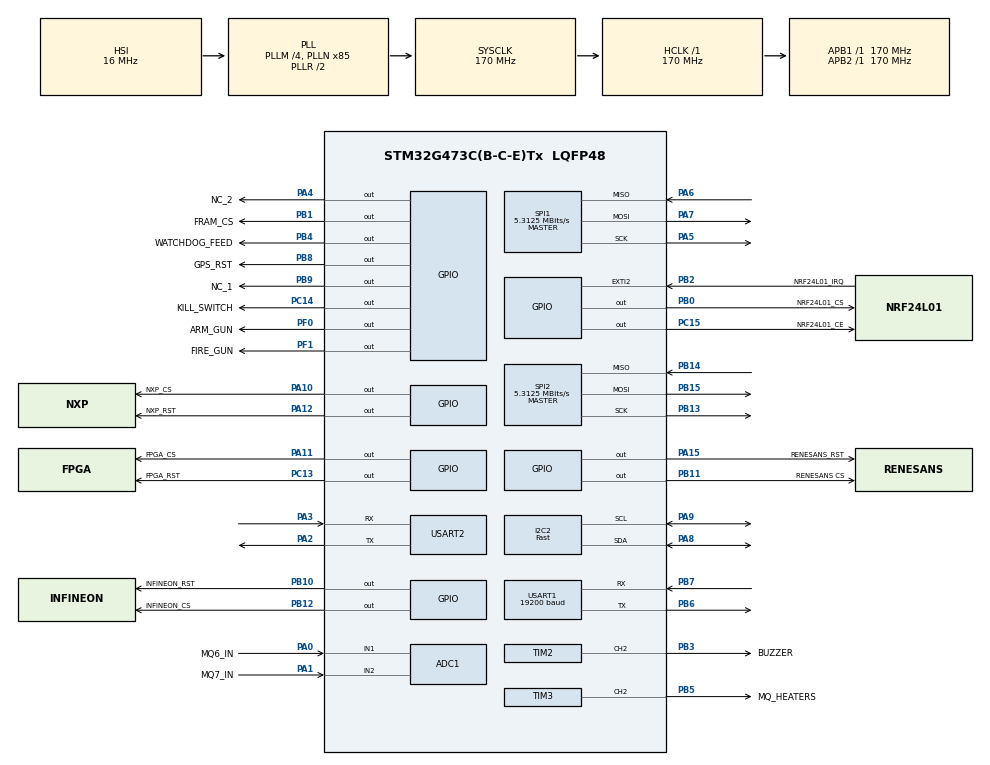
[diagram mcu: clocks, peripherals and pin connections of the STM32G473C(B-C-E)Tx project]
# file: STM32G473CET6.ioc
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ADC1.Channel-0\#ChannelRegularConversion=ADC_CHANNEL_1
ADC1.Channel-1\#ChannelRegularConversion=ADC_CHANNEL_2
ADC1.Channel-2\#ChannelRegularConversion=ADC_CHANNEL_VREFINT
ADC1.Channel-3\#ChannelRegularConversion=ADC_CHANNEL_TEMPSENSOR_ADC1
ADC1.ContinuousConvMode=DISABLE
ADC1.DMAContinuousRequests=DISABLE
ADC1.DataAlign=ADC_DATAALIGN_RIGHT
ADC1.EOCSelection=ADC_EOC_SEQ_CONV
ADC1.NbrOfConversion=4
ADC1.NbrOfConversionFlag=1
ADC1.OffsetNumber-1\#ChannelRegularConversion=ADC_OFFSET_NONE
ADC1.OffsetNumber-2\#ChannelRegularConversion=ADC_OFFSET_NONE
ADC1.OffsetNumber-3\#ChannelRegularConversion=ADC_OFFSET_NONE
ADC1.Overrun=ADC_OVR_DATA_PRESERVED
ADC1.Rank-1\#ChannelRegularConversion=2
ADC1.Rank-2\#ChannelRegularConversion=3
ADC1.Rank-3\#ChannelRegularConversion=4
ADC1.SamplingTime-0\#ChannelRegularConversion=ADC_SAMPLETIME_92CYCLES_5
ADC1.SamplingTime-1\#ChannelRegularConversion=ADC_SAMPLETIME_92CYCLES_5
ADC1.SamplingTime-2\#ChannelRegularConversion=ADC_SAMPLETIME_92CYCLES_5
ADC1.SamplingTime-3\#ChannelRegularConversion=ADC_SAMPLETIME_92CYCLES_5
ADC1.master=1
Dma.ADC1.10.Direction=DMA_PERIPH_TO_MEMORY
Dma.ADC1.10.EventEnable=DISABLE
Dma.ADC1.10.Instance=DMA2_Channel3
Dma.ADC1.10.MemDataAlignment=DMA_MDATAALIGN_WORD
Dma.ADC1.10.MemInc=DMA_MINC_ENABLE
Dma.ADC1.10.Mode=DMA_NORMAL
Dma.ADC1.10.PeriphDataAlignment=DMA_PDATAALIGN_WORD
Dma.ADC1.10.PeriphInc=DMA_PINC_DISABLE
Dma.ADC1.10.Polarity=HAL_DMAMUX_REQ_GEN_RISING
Dma.ADC1.10.Priority=DMA_PRIORITY_LOW
Dma.ADC1.10.RequestNumber=1
Dma.ADC1.10.SignalID=NONE
Dma.ADC1.10.SyncEnable=DISABLE
Dma.ADC1.10.SyncPolarity=HAL_DMAMUX_SYNC_NO_EVENT
Dma.ADC1.10.SyncRequestNumber=1
Dma.ADC1.10.SyncSignalID=NONE
Dma.I2C2_RX.1.Direction=DMA_PERIPH_TO_MEMORY
Dma.I2C2_RX.1.EventEnable=DISABLE
Dma.I2C2_RX.1.Instance=DMA1_Channel2
Dma.I2C2_RX.1.MemDataAlignment=DMA_MDATAALIGN_BYTE
Dma.I2C2_RX.1.MemInc=DMA_MINC_ENABLE
Dma.I2C2_RX.1.Mode=DMA_NORMAL
Dma.I2C2_RX.1.PeriphDataAlignment=DMA_PDATAALIGN_BYTE
Dma.I2C2_RX.1.PeriphInc=DMA_PINC_DISABLE
Dma.I2C2_RX.1.Polarity=HAL_DMAMUX_REQ_GEN_RISING
Dma.I2C2_RX.1.Priority=DMA_PRIORITY_MEDIUM
Dma.I2C2_RX.1.RequestNumber=1
Dma.I2C2_RX.1.SignalID=NONE
Dma.I2C2_RX.1.SyncEnable=DISABLE
Dma.I2C2_RX.1.SyncPolarity=HAL_DMAMUX_SYNC_NO_EVENT
Dma.I2C2_RX.1.SyncRequestNumber=1
Dma.I2C2_RX.1.SyncSignalID=NONE
Dma.I2C2_TX.0.Direction=DMA_MEMORY_TO_PERIPH
Dma.I2C2_TX.0.EventEnable=DISABLE
Dma.I2C2_TX.0.Instance=DMA1_Channel1
Dma.I2C2_TX.0.MemDataAlignment=DMA_MDATAALIGN_BYTE
Dma.I2C2_TX.0.MemInc=DMA_MINC_ENABLE
Dma.I2C2_TX.0.Mode=DMA_NORMAL
Dma.I2C2_TX.0.PeriphDataAlignment=DMA_PDATAALIGN_BYTE
Dma.I2C2_TX.0.PeriphInc=DMA_PINC_DISABLE
Dma.I2C2_TX.0.Polarity=HAL_DMAMUX_REQ_GEN_RISING
Dma.I2C2_TX.0.Priority=DMA_PRIORITY_MEDIUM
Dma.I2C2_TX.0.RequestNumber=1
Dma.I2C2_TX.0.SignalID=NONE
Dma.I2C2_TX.0.SyncEnable=DISABLE
Dma.I2C2_TX.0.SyncPolarity=HAL_DMAMUX_SYNC_NO_EVENT
Dma.I2C2_TX.0.SyncRequestNumber=1
Dma.I2C2_TX.0.SyncSignalID=NONE
Dma.Request0=I2C2_TX
Dma.Request1=I2C2_RX
Dma.Request10=ADC1
Dma.Request2=SPI1_RX
Dma.Request3=SPI1_TX
Dma.Request4=SPI2_RX
Dma.Request5=SPI2_TX
Dma.Request6=USART1_RX
Dma.Request7=USART1_TX
Dma.Request8=USART2_RX
Dma.Request9=USART2_TX
Dma.SPI1_RX.2.Direction=DMA_PERIPH_TO_MEMORY
Dma.SPI1_RX.2.EventEnable=DISABLE
Dma.SPI1_RX.2.Instance=DMA1_Channel3
Dma.SPI1_RX.2.MemDataAlignment=DMA_MDATAALIGN_BYTE
Dma.SPI1_RX.2.MemInc=DMA_MINC_ENABLE
Dma.SPI1_RX.2.Mode=DMA_NORMAL
Dma.SPI1_RX.2.PeriphDataAlignment=DMA_PDATAALIGN_BYTE
Dma.SPI1_RX.2.PeriphInc=DMA_PINC_DISABLE
Dma.SPI1_RX.2.Polarity=HAL_DMAMUX_REQ_GEN_RISING
Dma.SPI1_RX.2.Priority=DMA_PRIORITY_HIGH
Dma.SPI1_RX.2.RequestNumber=1
Dma.SPI1_RX.2.SignalID=NONE
Dma.SPI1_RX.2.SyncEnable=DISABLE
Dma.SPI1_RX.2.SyncPolarity=HAL_DMAMUX_SYNC_NO_EVENT
Dma.SPI1_RX.2.SyncRequestNumber=1
Dma.SPI1_RX.2.SyncSignalID=NONE
Dma.SPI1_TX.3.Direction=DMA_MEMORY_TO_PERIPH
Dma.SPI1_TX.3.EventEnable=DISABLE
Dma.SPI1_TX.3.Instance=DMA1_Channel4
Dma.SPI1_TX.3.MemDataAlignment=DMA_MDATAALIGN_BYTE
Dma.SPI1_TX.3.MemInc=DMA_MINC_ENABLE
Dma.SPI1_TX.3.Mode=DMA_NORMAL
Dma.SPI1_TX.3.PeriphDataAlignment=DMA_PDATAALIGN_BYTE
Dma.SPI1_TX.3.PeriphInc=DMA_PINC_DISABLE
Dma.SPI1_TX.3.Polarity=HAL_DMAMUX_REQ_GEN_RISING
Dma.SPI1_TX.3.Priority=DMA_PRIORITY_HIGH
Dma.SPI1_TX.3.RequestNumber=1
Dma.SPI1_TX.3.SignalID=NONE
Dma.SPI1_TX.3.SyncEnable=DISABLE
Dma.SPI1_TX.3.SyncPolarity=HAL_DMAMUX_SYNC_NO_EVENT
Dma.SPI1_TX.3.SyncRequestNumber=1
Dma.SPI1_TX.3.SyncSignalID=NONE
Dma.SPI2_RX.4.Direction=DMA_PERIPH_TO_MEMORY
Dma.SPI2_RX.4.EventEnable=DISABLE
Dma.SPI2_RX.4.Instance=DMA1_Channel5
Dma.SPI2_RX.4.MemDataAlignment=DMA_MDATAALIGN_BYTE
Dma.SPI2_RX.4.MemInc=DMA_MINC_ENABLE
Dma.SPI2_RX.4.Mode=DMA_NORMAL
Dma.SPI2_RX.4.PeriphDataAlignment=DMA_PDATAALIGN_BYTE
Dma.SPI2_RX.4.PeriphInc=DMA_PINC_DISABLE
Dma.SPI2_RX.4.Polarity=HAL_DMAMUX_REQ_GEN_RISING
Dma.SPI2_RX.4.Priority=DMA_PRIORITY_VERY_HIGH
Dma.SPI2_RX.4.RequestNumber=1
Dma.SPI2_RX.4.SignalID=NONE
Dma.SPI2_RX.4.SyncEnable=DISABLE
Dma.SPI2_RX.4.SyncPolarity=HAL_DMAMUX_SYNC_NO_EVENT
Dma.SPI2_RX.4.SyncRequestNumber=1
Dma.SPI2_RX.4.SyncSignalID=NONE
Dma.SPI2_TX.5.Direction=DMA_MEMORY_TO_PERIPH
Dma.SPI2_TX.5.EventEnable=DISABLE
Dma.SPI2_TX.5.Instance=DMA1_Channel6
Dma.SPI2_TX.5.MemDataAlignment=DMA_MDATAALIGN_BYTE
Dma.SPI2_TX.5.MemInc=DMA_MINC_ENABLE
Dma.SPI2_TX.5.Mode=DMA_NORMAL
Dma.SPI2_TX.5.PeriphDataAlignment=DMA_PDATAALIGN_BYTE
Dma.SPI2_TX.5.PeriphInc=DMA_PINC_DISABLE
Dma.SPI2_TX.5.Polarity=HAL_DMAMUX_REQ_GEN_RISING
Dma.SPI2_TX.5.Priority=DMA_PRIORITY_VERY_HIGH
Dma.SPI2_TX.5.RequestNumber=1
Dma.SPI2_TX.5.SignalID=NONE
Dma.SPI2_TX.5.SyncEnable=DISABLE
Dma.SPI2_TX.5.SyncPolarity=HAL_DMAMUX_SYNC_NO_EVENT
Dma.SPI2_TX.5.SyncRequestNumber=1
Dma.SPI2_TX.5.SyncSignalID=NONE
Dma.USART1_RX.6.Direction=DMA_PERIPH_TO_MEMORY
Dma.USART1_RX.6.EventEnable=DISABLE
Dma.USART1_RX.6.Instance=DMA1_Channel7
Dma.USART1_RX.6.MemDataAlignment=DMA_MDATAALIGN_BYTE
Dma.USART1_RX.6.MemInc=DMA_MINC_ENABLE
Dma.USART1_RX.6.Mode=DMA_CIRCULAR
Dma.USART1_RX.6.PeriphDataAlignment=DMA_PDATAALIGN_BYTE
Dma.USART1_RX.6.PeriphInc=DMA_PINC_DISABLE
Dma.USART1_RX.6.Polarity=HAL_DMAMUX_REQ_GEN_RISING
Dma.USART1_RX.6.Priority=DMA_PRIORITY_LOW
Dma.USART1_RX.6.RequestNumber=1
Dma.USART1_RX.6.SignalID=NONE
Dma.USART1_RX.6.SyncEnable=DISABLE
Dma.USART1_RX.6.SyncPolarity=HAL_DMAMUX_SYNC_NO_EVENT
Dma.USART1_RX.6.SyncRequestNumber=1
Dma.USART1_RX.6.SyncSignalID=NONE
Dma.USART1_TX.7.Direction=DMA_MEMORY_TO_PERIPH
Dma.USART1_TX.7.EventEnable=DISABLE
Dma.USART1_TX.7.Instance=DMA1_Channel8
Dma.USART1_TX.7.MemDataAlignment=DMA_MDATAALIGN_BYTE
Dma.USART1_TX.7.MemInc=DMA_MINC_ENABLE
Dma.USART1_TX.7.Mode=DMA_NORMAL
Dma.USART1_TX.7.PeriphDataAlignment=DMA_PDATAALIGN_BYTE
Dma.USART1_TX.7.PeriphInc=DMA_PINC_DISABLE
Dma.USART1_TX.7.Polarity=HAL_DMAMUX_REQ_GEN_RISING
Dma.USART1_TX.7.Priority=DMA_PRIORITY_LOW
Dma.USART1_TX.7.RequestNumber=1
Dma.USART1_TX.7.SignalID=NONE
Dma.USART1_TX.7.SyncEnable=DISABLE
Dma.USART1_TX.7.SyncPolarity=HAL_DMAMUX_SYNC_NO_EVENT
Dma.USART1_TX.7.SyncRequestNumber=1
Dma.USART1_TX.7.SyncSignalID=NONE
Dma.USART2_RX.8.Direction=DMA_PERIPH_TO_MEMORY
Dma.USART2_RX.8.EventEnable=DISABLE
Dma.USART2_RX.8.Instance=DMA2_Channel1
Dma.USART2_RX.8.MemDataAlignment=DMA_MDATAALIGN_BYTE
Dma.USART2_RX.8.MemInc=DMA_MINC_ENABLE
Dma.USART2_RX.8.Mode=DMA_NORMAL
Dma.USART2_RX.8.PeriphDataAlignment=DMA_PDATAALIGN_BYTE
Dma.USART2_RX.8.PeriphInc=DMA_PINC_DISABLE
Dma.USART2_RX.8.Polarity=HAL_DMAMUX_REQ_GEN_RISING
Dma.USART2_RX.8.Priority=DMA_PRIORITY_LOW
Dma.USART2_RX.8.RequestNumber=1
Dma.USART2_RX.8.SignalID=NONE
Dma.USART2_RX.8.SyncEnable=DISABLE
Dma.USART2_RX.8.SyncPolarity=HAL_DMAMUX_SYNC_NO_EVENT
Dma.USART2_RX.8.SyncRequestNumber=1
Dma.USART2_RX.8.SyncSignalID=NONE
Dma.USART2_TX.9.Direction=DMA_MEMORY_TO_PERIPH
Dma.USART2_TX.9.EventEnable=DISABLE
Dma.USART2_TX.9.Instance=DMA2_Channel2
Dma.USART2_TX.9.MemDataAlignment=DMA_MDATAALIGN_BYTE
Dma.USART2_TX.9.MemInc=DMA_MINC_ENABLE
Dma.USART2_TX.9.Mode=DMA_NORMAL
Dma.USART2_TX.9.PeriphDataAlignment=DMA_PDATAALIGN_BYTE
Dma.USART2_TX.9.PeriphInc=DMA_PINC_DISABLE
Dma.USART2_TX.9.Polarity=HAL_DMAMUX_REQ_GEN_RISING
Dma.USART2_TX.9.Priority=DMA_PRIORITY_LOW
Dma.USART2_TX.9.RequestNumber=1
Dma.USART2_TX.9.SignalID=NONE
Dma.USART2_TX.9.SyncEnable=DISABLE
Dma.USART2_TX.9.SyncPolarity=HAL_DMAMUX_SYNC_NO_EVENT
Dma.USART2_TX.9.SyncRequestNumber=1
Dma.USART2_TX.9.SyncSignalID=NONE
I2C2.I2C_Speed_Mode=I2C_Fast
I2C2.Timing=0x40621236
Mcu.Family=STM32G4
Mcu.Name=STM32G473C(B-C-E)Tx
Mcu.Package=LQFP48
NVIC.DMA1_Channel1_IRQn=true\:8\:0\:true\:false\:true\:false\:false\:true\:true
NVIC.DMA1_Channel2_IRQn=true\:8\:0\:true\:false\:true\:false\:false\:true\:true
NVIC.DMA1_Channel3_IRQn=true\:2\:0\:true\:false\:true\:false\:false\:true\:true
NVIC.DMA1_Channel4_IRQn=true\:2\:0\:true\:false\:true\:false\:false\:true\:true
NVIC.DMA1_Channel5_IRQn=true\:5\:0\:true\:false\:true\:false\:false\:true\:true
NVIC.DMA1_Channel6_IRQn=true\:5\:0\:true\:false\:true\:false\:false\:true\:true
NVIC.DMA1_Channel7_IRQn=true\:9\:0\:true\:false\:true\:false\:false\:true\:true
NVIC.DMA1_Channel8_IRQn=true\:9\:0\:true\:false\:true\:false\:false\:true\:true
NVIC.DMA2_Channel1_IRQn=true\:0\:0\:false\:false\:true\:false\:false\:true\:true
NVIC.DMA2_Channel2_IRQn=true\:0\:0\:false\:false\:true\:false\:false\:true\:true
NVIC.DMA2_Channel3_IRQn=true\:3\:0\:true\:false\:true\:true\:false\:true\:true
NVIC.EXTI2_IRQn=true\:5\:0\:true\:false\:true\:false\:true\:true\:true
NVIC.PriorityGroup=NVIC_PRIORITYGROUP_4
NVIC.TIM6_DAC_IRQn=true\:15\:0\:true\:false\:true\:false\:false\:true\:true
NVIC.TimeBase=TIM6_DAC_IRQn
NVIC.TimeBaseIP=TIM6
NVIC.USART1_IRQn=true\:0\:0\:false\:false\:true\:false\:true\:true\:true
NVIC.USART2_IRQn=true\:0\:0\:false\:false\:true\:false\:true\:true\:true
PA0.GPIO_Label=MQ6_IN
PA0.Mode=IN1-Single-Ended
PA0.Signal=ADC1_IN1
PA1.GPIO_Label=MQ7_IN
PA1.Mode=IN2-Single-Ended
PA1.Signal=ADC1_IN2
PA10.GPIO_Label=NXP_CS
PA10.Signal=GPIO_Output
PA11.GPIO_Label=FPGA_CS
PA11.Signal=GPIO_Output
PA12.GPIO_Label=NXP_RST
PA12.Signal=GPIO_Output
PA13.Mode=Serial_Wire
PA13.Signal=SYS_JTMS-SWDIO
PA14.Mode=Serial_Wire
PA14.Signal=SYS_JTCK-SWCLK
PA15.GPIO_Label=RENESANS_RST
PA15.Signal=GPIO_Output
PA2.Mode=Asynchronous
PA2.Signal=USART2_TX
PA3.GPIO_PuPd=GPIO_PULLUP
PA3.Mode=Asynchronous
PA3.Signal=USART2_RX
PA4.GPIO_Label=NC_2
PA4.Signal=GPIO_Output
PA5.GPIO_Speed=GPIO_SPEED_FREQ_HIGH
PA5.Mode=Full_Duplex_Master
PA5.Signal=SPI1_SCK
PA6.GPIO_Speed=GPIO_SPEED_FREQ_HIGH
PA6.Mode=Full_Duplex_Master
PA6.Signal=SPI1_MISO
PA7.GPIO_Speed=GPIO_SPEED_FREQ_HIGH
PA7.Mode=Full_Duplex_Master
PA7.Signal=SPI1_MOSI
PA8.Mode=I2C
PA8.Signal=I2C2_SDA
PA9.Mode=I2C
PA9.Signal=I2C2_SCL
PB0.GPIO_Label=NRF24L01_CS
PB0.Signal=GPIO_Output
PB1.GPIO_Label=FRAM_CS
PB1.Signal=GPIO_Output
PB10.GPIO_Label=INFINEON_RST
PB10.Signal=GPIO_Output
PB11.GPIO_Label=RENESANS CS
PB11.Signal=GPIO_Output
PB12.GPIO_Label=INFINEON_CS
PB12.Signal=GPIO_Output
PB13.GPIO_Speed=GPIO_SPEED_FREQ_VERY_HIGH
PB13.Mode=Full_Duplex_Master
PB13.Signal=SPI2_SCK
PB14.GPIO_Speed=GPIO_SPEED_FREQ_VERY_HIGH
PB14.Mode=Full_Duplex_Master
PB14.Signal=SPI2_MISO
PB15.GPIO_PuPd=GPIO_NOPULL
PB15.GPIO_Speed=GPIO_SPEED_FREQ_VERY_HIGH
PB15.Mode=Full_Duplex_Master
PB15.Signal=SPI2_MOSI
PB2.GPIO_Label=NRF24L01_IRQ
PB2.GPIO_ModeDefaultEXTI=GPIO_MODE_IT_FALLING
PB2.GPIO_PuPd=GPIO_NOPULL
PB2.Signal=GPXTI2
PB3.GPIO_Label=BUZZER
PB3.GPIO_Speed=GPIO_SPEED_FREQ_LOW
PB3.Signal=S_TIM2_CH2
PB4.GPIO_Label=WATCHDOG_FEED
PB4.Signal=GPIO_Output
PB5.GPIO_Label=MQ_HEATERS
PB5.GPIO_Speed=GPIO_SPEED_FREQ_VERY_HIGH
PB5.Signal=S_TIM3_CH2
PB6.Mode=Asynchronous
PB6.Signal=USART1_TX
PB7.GPIO_ModeDefaultPP=GPIO_MODE_AF_PP
PB7.GPIO_PuPd=GPIO_PULLUP
PB7.Mode=Asynchronous
PB7.Signal=USART1_RX
PB8-BOOT0.GPIO_Label=GPS_RST
PB8-BOOT0.Signal=GPIO_Output
PB9.GPIO_Label=NC_1
PB9.Signal=GPIO_Output
PC13.GPIO_Label=FPGA_RST
PC13.Signal=GPIO_Output
PC14-OSC32_IN.GPIO_Label=KILL_SWITCH
PC14-OSC32_IN.Signal=GPIO_Output
PC15-OSC32_OUT.GPIO_Label=NRF24L01_CE
PC15-OSC32_OUT.Signal=GPIO_Output
PF0-OSC_IN.GPIO_Label=ARM_GUN
PF0-OSC_IN.Signal=GPIO_Output
PF1-OSC_OUT.GPIO_Label=FIRE_GUN
PF1-OSC_OUT.Signal=GPIO_Output
ProjectManager.HeapSize=0x200
ProjectManager.StackSize=0x400
ProjectManager.TargetToolchain=STM32CubeIDE
RCC.ADC12Freq_Value=170000000
RCC.ADC345Freq_Value=170000000
RCC.AHBFreq_Value=170000000
RCC.APB1Freq_Value=170000000
RCC.APB1TimFreq_Value=170000000
RCC.APB2Freq_Value=170000000
RCC.APB2TimFreq_Value=170000000
RCC.CortexFreq_Value=170000000
RCC.EXTERNAL_CLOCK_VALUE=12288000
RCC.HCLKFreq_Value=170000000
RCC.HSE_VALUE=8000000
RCC.HSI48_VALUE=48000000
RCC.HSI_VALUE=16000000
RCC.LSE_VALUE=32768
RCC.PLLM=RCC_PLLM_DIV4
RCC.PLLN=85
RCC.SYSCLKFreq_VALUE=170000000
RCC.SYSCLKSource=RCC_SYSCLKSOURCE_PLLCLK
RCC.USBFreq_Value=170000000
RCC.VCOOutputFreq_Value=340000000
SH.S_TIM2_CH2.0=TIM2_CH2,PWM Generation2 CH2
SH.S_TIM3_CH2.0=TIM3_CH2,PWM Generation2 CH2
SPI1.BaudRatePrescaler=SPI_BAUDRATEPRESCALER_32
SPI1.CalculateBaudRate=5.3125 MBits/s
SPI1.DataSize=SPI_DATASIZE_8BIT
SPI1.Direction=SPI_DIRECTION_2LINES
SPI1.FirstBit=SPI_FIRSTBIT_MSB
SPI1.Mode=SPI_MODE_MASTER
SPI1.VirtualType=VM_MASTER
SPI2.BaudRatePrescaler=SPI_BAUDRATEPRESCALER_32
SPI2.CalculateBaudRate=5.3125 MBits/s
SPI2.DataSize=SPI_DATASIZE_8BIT
SPI2.Direction=SPI_DIRECTION_2LINES
SPI2.Mode=SPI_MODE_MASTER
SPI2.VirtualType=VM_MASTER
STMicroelectronics.X-CUBE-AZRTOS-G4.2.0.0.AZRTOS_APP_MEM_ALLOCATION_METHOD=1
STMicroelectronics.X-CUBE-AZRTOS-G4.2.0.0.TX_APP_GENERATE_INIT_CODE=true
STMicroelectronics.X-CUBE-AZRTOS-G4.2.0.0.TX_TIMER_TICKS_PER_SECOND=2000
STMicroelectronics.X-CUBE-AZRTOS-G4.2.0.0.ThreadXCcRTOSJjThreadXJjCore=true
STMicroelectronics.X-CUBE-AZRTOS-G4.2.0.0_IsAnAzureRtosMw=true
TIM2.AutoReloadPreload=TIM_AUTORELOAD_PRELOAD_ENABLE
TIM2.Channel-PWM\ Generation2\ CH2=TIM_CHANNEL_2
TIM2.PeriodNoDither=999
TIM2.Prescaler=169
TIM3.AutoReloadPreload=TIM_AUTORELOAD_PRELOAD_ENABLE
TIM3.Channel-PWM\ Generation2\ CH2=TIM_CHANNEL_2
TIM3.PeriodNoDither=999
TIM3.Prescaler=169
USART1.BaudRate=19200
USART1.VirtualMode-Asynchronous=VM_ASYNC
USART2.VirtualMode-Asynchronous=VM_ASYNC
VP_ADC1_TempSens_Input.Mode=IN-TempSens
VP_ADC1_Vref_Input.Mode=IN-Vrefint
VP_CORDIC_VS_CORDIC.Mode=CORDIC_Activate
VP_STMicroelectronics.X-CUBE-AZRTOS-G4_VS_RTOSJjThreadX_6.2.0_2.0.0.Mode=RTOSJjThreadX
VP_SYS_VS_DBSignals.Mode=DisableDeadBatterySignals
VP_SYS_VS_tim6.Mode=TIM6
VP_TIM2_VS_ClockSourceINT.Mode=Internal
VP_TIM3_VS_ClockSourceINT.Mode=Internal
board=custom

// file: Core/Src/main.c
/* USER CODE BEGIN Header */
/**
  ******************************************************************************
  * @file           : main.c
  * @brief          : Main program body
  ******************************************************************************
  * @attention
  *
  * Copyright (c) 2025 STMicroelectronics.
  * All rights reserved.
  *
  * This software is licensed under terms that can be found in the LICENSE file
  * in the root directory of this software component.
  * If no LICENSE file comes with this software, it is provided AS-IS.
  *
  ******************************************************************************
  */
/* USER CODE END Header */
#include "app_threadx.h"
#include "main.h"

ADC_HandleTypeDef hadc1;
DMA_HandleTypeDef hdma_adc1;

CORDIC_HandleTypeDef hcordic;

I2C_HandleTypeDef hi2c2;
DMA_HandleTypeDef hdma_i2c2_tx;
DMA_HandleTypeDef hdma_i2c2_rx;

SPI_HandleTypeDef hspi1;
SPI_HandleTypeDef hspi2;
DMA_HandleTypeDef hdma_spi1_rx;
DMA_HandleTypeDef hdma_spi1_tx;
DMA_HandleTypeDef hdma_spi2_rx;
DMA_HandleTypeDef hdma_spi2_tx;

TIM_HandleTypeDef htim2;
TIM_HandleTypeDef htim3;

UART_HandleTypeDef huart1;
UART_HandleTypeDef huart2;
DMA_HandleTypeDef hdma_usart1_rx;
DMA_HandleTypeDef hdma_usart1_tx;
DMA_HandleTypeDef hdma_usart2_rx;
DMA_HandleTypeDef hdma_usart2_tx;

void SystemClock_Config(void);
static void MX_GPIO_Init(void);
static void MX_DMA_Init(void);
static void MX_ADC1_Init(void);
static void MX_I2C2_Init(void);
static void MX_SPI1_Init(void);
static void MX_SPI2_Init(void);
static void MX_USART1_UART_Init(void);
static void MX_USART2_UART_Init(void);
static void MX_CORDIC_Init(void);
static void MX_TIM3_Init(void);
static void MX_TIM2_Init(void);

int main(void)
{

  /* MCU Configuration--------------------------------------------------------*/

  /* Reset of all peripherals, Initializes the Flash interface and the Systick. */
  HAL_Init();

  /* Configure the system clock */
  SystemClock_Config();

  /* Initialize all configured peripherals */
  MX_GPIO_Init();
  MX_DMA_Init();
  MX_ADC1_Init();
  MX_I2C2_Init();
  MX_SPI1_Init();
  MX_SPI2_Init();
  MX_USART1_UART_Init();
  MX_USART2_UART_Init();
  MX_CORDIC_Init();
  MX_TIM3_Init();
  MX_TIM2_Init();

  MX_ThreadX_Init();

  /* We should never get here as control is now taken by the scheduler */

  /* Infinite loop */
  while (1)
  {

  }
}

void SystemClock_Config(void)
{
  RCC_OscInitTypeDef RCC_OscInitStruct = {0};
  RCC_ClkInitTypeDef RCC_ClkInitStruct = {0};

  /** Configure the main internal regulator output voltage
  */
  HAL_PWREx_ControlVoltageScaling(PWR_REGULATOR_VOLTAGE_SCALE1_BOOST);

  /** Initializes the RCC Oscillators according to the specified parameters
  * in the RCC_OscInitTypeDef structure.
  */
  RCC_OscInitStruct.OscillatorType = RCC_OSCILLATORTYPE_HSI;
  RCC_OscInitStruct.HSIState = RCC_HSI_ON;
  RCC_OscInitStruct.HSICalibrationValue = RCC_HSICALIBRATION_DEFAULT;
  RCC_OscInitStruct.PLL.PLLState = RCC_PLL_ON;
  RCC_OscInitStruct.PLL.PLLSource = RCC_PLLSOURCE_HSI;
  RCC_OscInitStruct.PLL.PLLM = RCC_PLLM_DIV4;
  RCC_OscInitStruct.PLL.PLLN = 85;
  RCC_OscInitStruct.PLL.PLLP = RCC_PLLP_DIV2;
  RCC_OscInitStruct.PLL.PLLQ = RCC_PLLQ_DIV2;
  RCC_OscInitStruct.PLL.PLLR = RCC_PLLR_DIV2;
  if (HAL_RCC_OscConfig(&RCC_OscInitStruct) != HAL_OK)
  {
    Error_Handler();
  }

  /** Initializes the CPU, AHB and APB buses clocks
  */
  RCC_ClkInitStruct.ClockType = RCC_CLOCKTYPE_HCLK|RCC_CLOCKTYPE_SYSCLK
                              |RCC_CLOCKTYPE_PCLK1|RCC_CLOCKTYPE_PCLK2;
  RCC_ClkInitStruct.SYSCLKSource = RCC_SYSCLKSOURCE_PLLCLK;
  RCC_ClkInitStruct.AHBCLKDivider = RCC_SYSCLK_DIV1;
  RCC_ClkInitStruct.APB1CLKDivider = RCC_HCLK_DIV1;
  RCC_ClkInitStruct.APB2CLKDivider = RCC_HCLK_DIV1;

  if (HAL_RCC_ClockConfig(&RCC_ClkInitStruct, FLASH_LATENCY_4) != HAL_OK)
  {
    Error_Handler();
  }
}

static void MX_ADC1_Init(void)
{

  ADC_MultiModeTypeDef multimode = {0};
  ADC_ChannelConfTypeDef sConfig = {0};

  /** Common config
  */
  hadc1.Instance = ADC1;
  hadc1.Init.ClockPrescaler = ADC_CLOCK_SYNC_PCLK_DIV4;
  hadc1.Init.Resolution = ADC_RESOLUTION_12B;
  hadc1.Init.DataAlign = ADC_DATAALIGN_RIGHT;
  hadc1.Init.GainCompensation = 0;
  hadc1.Init.ScanConvMode = ADC_SCAN_ENABLE;
  hadc1.Init.EOCSelection = ADC_EOC_SEQ_CONV;
  hadc1.Init.LowPowerAutoWait = DISABLE;
  hadc1.Init.ContinuousConvMode = DISABLE;
  hadc1.Init.NbrOfConversion = 4;
  hadc1.Init.DiscontinuousConvMode = DISABLE;
  hadc1.Init.ExternalTrigConv = ADC_SOFTWARE_START;
  hadc1.Init.ExternalTrigConvEdge = ADC_EXTERNALTRIGCONVEDGE_NONE;
  hadc1.Init.DMAContinuousRequests = DISABLE;
  hadc1.Init.Overrun = ADC_OVR_DATA_PRESERVED;
  hadc1.Init.OversamplingMode = DISABLE;
  if (HAL_ADC_Init(&hadc1) != HAL_OK)
  {
    Error_Handler();
  }

  /** Configure the ADC multi-mode
  */
  multimode.Mode = ADC_MODE_INDEPENDENT;
  if (HAL_ADCEx_MultiModeConfigChannel(&hadc1, &multimode) != HAL_OK)
  {
    Error_Handler();
  }

  /** Configure Regular Channel
  */
  sConfig.Channel = ADC_CHANNEL_1;
  sConfig.Rank = ADC_REGULAR_RANK_1;
  sConfig.SamplingTime = ADC_SAMPLETIME_92CYCLES_5;
  sConfig.SingleDiff = ADC_SINGLE_ENDED;
  sConfig.OffsetNumber = ADC_OFFSET_NONE;
  sConfig.Offset = 0;
  if (HAL_ADC_ConfigChannel(&hadc1, &sConfig) != HAL_OK)
  {
    Error_Handler();
  }

  /** Configure Regular Channel
  */
  sConfig.Channel = ADC_CHANNEL_2;
  sConfig.Rank = ADC_REGULAR_RANK_2;
  if (HAL_ADC_ConfigChannel(&hadc1, &sConfig) != HAL_OK)
  {
    Error_Handler();
  }

  /** Configure Regular Channel
  */
  sConfig.Channel = ADC_CHANNEL_VREFINT;
  sConfig.Rank = ADC_REGULAR_RANK_3;
  if (HAL_ADC_ConfigChannel(&hadc1, &sConfig) != HAL_OK)
  {
    Error_Handler();
  }

  /** Configure Regular Channel
  */
  sConfig.Channel = ADC_CHANNEL_TEMPSENSOR_ADC1;
  sConfig.Rank = ADC_REGULAR_RANK_4;
  if (HAL_ADC_ConfigChannel(&hadc1, &sConfig) != HAL_OK)
  {
    Error_Handler();
  }

}

static void MX_CORDIC_Init(void)
{

  hcordic.Instance = CORDIC;
  if (HAL_CORDIC_Init(&hcordic) != HAL_OK)
  {
    Error_Handler();
  }

}

static void MX_I2C2_Init(void)
{

  hi2c2.Instance = I2C2;
  hi2c2.Init.Timing = 0x40621236;
  hi2c2.Init.OwnAddress1 = 0;
  hi2c2.Init.AddressingMode = I2C_ADDRESSINGMODE_7BIT;
  hi2c2.Init.DualAddressMode = I2C_DUALADDRESS_DISABLE;
  hi2c2.Init.OwnAddress2 = 0;
  hi2c2.Init.OwnAddress2Masks = I2C_OA2_NOMASK;
  hi2c2.Init.GeneralCallMode = I2C_GENERALCALL_DISABLE;
  hi2c2.Init.NoStretchMode = I2C_NOSTRETCH_DISABLE;
  if (HAL_I2C_Init(&hi2c2) != HAL_OK)
  {
    Error_Handler();
  }

  /** Configure Analogue filter
  */
  if (HAL_I2CEx_ConfigAnalogFilter(&hi2c2, I2C_ANALOGFILTER_ENABLE) != HAL_OK)
  {
    Error_Handler();
  }

  /** Configure Digital filter
  */
  if (HAL_I2CEx_ConfigDigitalFilter(&hi2c2, 0) != HAL_OK)
  {
    Error_Handler();
  }

}

static void MX_SPI1_Init(void)
{

  /* SPI1 parameter configuration*/
  hspi1.Instance = SPI1;
  hspi1.Init.Mode = SPI_MODE_MASTER;
  hspi1.Init.Direction = SPI_DIRECTION_2LINES;
  hspi1.Init.DataSize = SPI_DATASIZE_8BIT;
  hspi1.Init.CLKPolarity = SPI_POLARITY_LOW;
  hspi1.Init.CLKPhase = SPI_PHASE_1EDGE;
  hspi1.Init.NSS = SPI_NSS_SOFT;
  hspi1.Init.BaudRatePrescaler = SPI_BAUDRATEPRESCALER_32;
  hspi1.Init.FirstBit = SPI_FIRSTBIT_MSB;
  hspi1.Init.TIMode = SPI_TIMODE_DISABLE;
  hspi1.Init.CRCCalculation = SPI_CRCCALCULATION_DISABLE;
  hspi1.Init.CRCPolynomial = 7;
  hspi1.Init.CRCLength = SPI_CRC_LENGTH_DATASIZE;
  hspi1.Init.NSSPMode = SPI_NSS_PULSE_ENABLE;
  if (HAL_SPI_Init(&hspi1) != HAL_OK)
  {
    Error_Handler();
  }

}

static void MX_SPI2_Init(void)
{

  /* SPI2 parameter configuration*/
  hspi2.Instance = SPI2;
  hspi2.Init.Mode = SPI_MODE_MASTER;
  hspi2.Init.Direction = SPI_DIRECTION_2LINES;
  hspi2.Init.DataSize = SPI_DATASIZE_8BIT;
  hspi2.Init.CLKPolarity = SPI_POLARITY_LOW;
  hspi2.Init.CLKPhase = SPI_PHASE_1EDGE;
  hspi2.Init.NSS = SPI_NSS_SOFT;
  hspi2.Init.BaudRatePrescaler = SPI_BAUDRATEPRESCALER_32;
  hspi2.Init.FirstBit = SPI_FIRSTBIT_MSB;
  hspi2.Init.TIMode = SPI_TIMODE_DISABLE;
  hspi2.Init.CRCCalculation = SPI_CRCCALCULATION_DISABLE;
  hspi2.Init.CRCPolynomial = 7;
  hspi2.Init.CRCLength = SPI_CRC_LENGTH_DATASIZE;
  hspi2.Init.NSSPMode = SPI_NSS_PULSE_ENABLE;
  if (HAL_SPI_Init(&hspi2) != HAL_OK)
  {
    Error_Handler();
  }

}

static void MX_TIM2_Init(void)
{

  TIM_ClockConfigTypeDef sClockSourceConfig = {0};
  TIM_MasterConfigTypeDef sMasterConfig = {0};
  TIM_OC_InitTypeDef sConfigOC = {0};

  htim2.Instance = TIM2;
  htim2.Init.Prescaler = 169;
  htim2.Init.CounterMode = TIM_COUNTERMODE_UP;
  htim2.Init.Period = 999;
  htim2.Init.ClockDivision = TIM_CLOCKDIVISION_DIV1;
  htim2.Init.AutoReloadPreload = TIM_AUTORELOAD_PRELOAD_ENABLE;
  if (HAL_TIM_Base_Init(&htim2) != HAL_OK)
  {
    Error_Handler();
  }
  sClockSourceConfig.ClockSource = TIM_CLOCKSOURCE_INTERNAL;
  if (HAL_TIM_ConfigClockSource(&htim2, &sClockSourceConfig) != HAL_OK)
  {
    Error_Handler();
  }
  if (HAL_TIM_PWM_Init(&htim2) != HAL_OK)
  {
    Error_Handler();
  }
  sMasterConfig.MasterOutputTrigger = TIM_TRGO_RESET;
  sMasterConfig.MasterSlaveMode = TIM_MASTERSLAVEMODE_DISABLE;
  if (HAL_TIMEx_MasterConfigSynchronization(&htim2, &sMasterConfig) != HAL_OK)
  {
    Error_Handler();
  }
  sConfigOC.OCMode = TIM_OCMODE_PWM1;
  sConfigOC.Pulse = 0;
  sConfigOC.OCPolarity = TIM_OCPOLARITY_HIGH;
  sConfigOC.OCFastMode = TIM_OCFAST_DISABLE;
  if (HAL_TIM_PWM_ConfigChannel(&htim2, &sConfigOC, TIM_CHANNEL_2) != HAL_OK)
  {
    Error_Handler();
  }
  HAL_TIM_MspPostInit(&htim2);

}

static void MX_TIM3_Init(void)
{

  TIM_ClockConfigTypeDef sClockSourceConfig = {0};
  TIM_MasterConfigTypeDef sMasterConfig = {0};
  TIM_OC_InitTypeDef sConfigOC = {0};

  htim3.Instance = TIM3;
  htim3.Init.Prescaler = 169;
  htim3.Init.CounterMode = TIM_COUNTERMODE_UP;
  htim3.Init.Period = 999;
  htim3.Init.ClockDivision = TIM_CLOCKDIVISION_DIV1;
  htim3.Init.AutoReloadPreload = TIM_AUTORELOAD_PRELOAD_ENABLE;
  if (HAL_TIM_Base_Init(&htim3) != HAL_OK)
  {
    Error_Handler();
  }
  sClockSourceConfig.ClockSource = TIM_CLOCKSOURCE_INTERNAL;
  if (HAL_TIM_ConfigClockSource(&htim3, &sClockSourceConfig) != HAL_OK)
  {
    Error_Handler();
  }
  if (HAL_TIM_PWM_Init(&htim3) != HAL_OK)
  {
    Error_Handler();
  }
  sMasterConfig.MasterOutputTrigger = TIM_TRGO_RESET;
  sMasterConfig.MasterSlaveMode = TIM_MASTERSLAVEMODE_DISABLE;
  if (HAL_TIMEx_MasterConfigSynchronization(&htim3, &sMasterConfig) != HAL_OK)
  {
    Error_Handler();
  }
  sConfigOC.OCMode = TIM_OCMODE_PWM1;
  sConfigOC.Pulse = 0;
  sConfigOC.OCPolarity = TIM_OCPOLARITY_HIGH;
  sConfigOC.OCFastMode = TIM_OCFAST_DISABLE;
  if (HAL_TIM_PWM_ConfigChannel(&htim3, &sConfigOC, TIM_CHANNEL_2) != HAL_OK)
  {
    Error_Handler();
  }
  /* USER CODE BEGIN TIM3_Init 2 */
  __HAL_TIM_ENABLE_OCxPRELOAD(&htim3, TIM_CHANNEL_2);
  /* USER CODE END TIM3_Init 2 */
  HAL_TIM_MspPostInit(&htim3);

}

static void MX_USART1_UART_Init(void)
{

  huart1.Instance = USART1;
  huart1.Init.BaudRate = 19200;
  huart1.Init.WordLength = UART_WORDLENGTH_8B;
  huart1.Init.StopBits = UART_STOPBITS_1;
  huart1.Init.Parity = UART_PARITY_NONE;
  huart1.Init.Mode = UART_MODE_TX_RX;
  huart1.Init.HwFlowCtl = UART_HWCONTROL_NONE;
  huart1.Init.OverSampling = UART_OVERSAMPLING_16;
  huart1.Init.OneBitSampling = UART_ONE_BIT_SAMPLE_DISABLE;
  huart1.Init.ClockPrescaler = UART_PRESCALER_DIV1;
  huart1.AdvancedInit.AdvFeatureInit = UART_ADVFEATURE_NO_INIT;
  if (HAL_UART_Init(&huart1) != HAL_OK)
  {
    Error_Handler();
  }
  if (HAL_UARTEx_SetTxFifoThreshold(&huart1, UART_TXFIFO_THRESHOLD_1_8) != HAL_OK)
  {
    Error_Handler();
  }
  if (HAL_UARTEx_SetRxFifoThreshold(&huart1, UART_RXFIFO_THRESHOLD_1_8) != HAL_OK)
  {
    Error_Handler();
  }
  if (HAL_UARTEx_DisableFifoMode(&huart1) != HAL_OK)
  {
    Error_Handler();
  }

}

static void MX_USART2_UART_Init(void)
{

  huart2.Instance = USART2;
  huart2.Init.BaudRate = 115200;
  huart2.Init.WordLength = UART_WORDLENGTH_8B;
  huart2.Init.StopBits = UART_STOPBITS_1;
  huart2.Init.Parity = UART_PARITY_NONE;
  huart2.Init.Mode = UART_MODE_TX_RX;
  huart2.Init.HwFlowCtl = UART_HWCONTROL_NONE;
  huart2.Init.OverSampling = UART_OVERSAMPLING_16;
  huart2.Init.OneBitSampling = UART_ONE_BIT_SAMPLE_DISABLE;
  huart2.Init.ClockPrescaler = UART_PRESCALER_DIV1;
  huart2.AdvancedInit.AdvFeatureInit = UART_ADVFEATURE_NO_INIT;
  if (HAL_UART_Init(&huart2) != HAL_OK)
  {
    Error_Handler();
  }
  if (HAL_UARTEx_SetTxFifoThreshold(&huart2, UART_TXFIFO_THRESHOLD_1_8) != HAL_OK)
  {
    Error_Handler();
  }
  if (HAL_UARTEx_SetRxFifoThreshold(&huart2, UART_RXFIFO_THRESHOLD_1_8) != HAL_OK)
  {
    Error_Handler();
  }
  if (HAL_UARTEx_DisableFifoMode(&huart2) != HAL_OK)
  {
    Error_Handler();
  }

}

static void MX_DMA_Init(void)
{

  /* DMA controller clock enable */
  __HAL_RCC_DMAMUX1_CLK_ENABLE();
  __HAL_RCC_DMA1_CLK_ENABLE();
  __HAL_RCC_DMA2_CLK_ENABLE();

  /* DMA interrupt init */
  /* DMA1_Channel1_IRQn interrupt configuration */
  HAL_NVIC_SetPriority(DMA1_Channel1_IRQn, 8, 0);
  HAL_NVIC_EnableIRQ(DMA1_Channel1_IRQn);
  /* DMA1_Channel2_IRQn interrupt configuration */
  HAL_NVIC_SetPriority(DMA1_Channel2_IRQn, 8, 0);
  HAL_NVIC_EnableIRQ(DMA1_Channel2_IRQn);
  /* DMA1_Channel3_IRQn interrupt configuration */
  HAL_NVIC_SetPriority(DMA1_Channel3_IRQn, 2, 0);
  HAL_NVIC_EnableIRQ(DMA1_Channel3_IRQn);
  /* DMA1_Channel4_IRQn interrupt configuration */
  HAL_NVIC_SetPriority(DMA1_Channel4_IRQn, 2, 0);
  HAL_NVIC_EnableIRQ(DMA1_Channel4_IRQn);
  /* DMA1_Channel5_IRQn interrupt configuration */
  HAL_NVIC_SetPriority(DMA1_Channel5_IRQn, 5, 0);
  HAL_NVIC_EnableIRQ(DMA1_Channel5_IRQn);
  /* DMA1_Channel6_IRQn interrupt configuration */
  HAL_NVIC_SetPriority(DMA1_Channel6_IRQn, 5, 0);
  HAL_NVIC_EnableIRQ(DMA1_Channel6_IRQn);
  /* DMA1_Channel7_IRQn interrupt configuration */
  HAL_NVIC_SetPriority(DMA1_Channel7_IRQn, 9, 0);
  HAL_NVIC_EnableIRQ(DMA1_Channel7_IRQn);
  /* DMA2_Channel1_IRQn interrupt configuration */
  HAL_NVIC_SetPriority(DMA2_Channel1_IRQn, 0, 0);
  HAL_NVIC_EnableIRQ(DMA2_Channel1_IRQn);
  /* DMA2_Channel2_IRQn interrupt configuration */
  HAL_NVIC_SetPriority(DMA2_Channel2_IRQn, 0, 0);
  HAL_NVIC_EnableIRQ(DMA2_Channel2_IRQn);
  /* DMA2_Channel3_IRQn interrupt configuration */
  HAL_NVIC_SetPriority(DMA2_Channel3_IRQn, 3, 0);
  HAL_NVIC_EnableIRQ(DMA2_Channel3_IRQn);
  /* DMA1_Channel8_IRQn interrupt configuration */
  HAL_NVIC_SetPriority(DMA1_Channel8_IRQn, 9, 0);
  HAL_NVIC_EnableIRQ(DMA1_Channel8_IRQn);

}

static void MX_GPIO_Init(void)
{
  GPIO_InitTypeDef GPIO_InitStruct = {0};

  /* GPIO Ports Clock Enable */
  __HAL_RCC_GPIOC_CLK_ENABLE();
  __HAL_RCC_GPIOF_CLK_ENABLE();
  __HAL_RCC_GPIOA_CLK_ENABLE();
  __HAL_RCC_GPIOB_CLK_ENABLE();

  /*Configure GPIO pin Output Level */
  HAL_GPIO_WritePin(GPIOC, FPGA_RST_Pin|KILL_SWITCH_Pin|NRF24L01_CE_Pin, GPIO_PIN_RESET);

  /*Configure GPIO pin Output Level */
  HAL_GPIO_WritePin(GPIOF, ARM_GUN_Pin|FIRE_GUN_Pin, GPIO_PIN_RESET);

  /*Configure GPIO pin Output Level */
  HAL_GPIO_WritePin(GPIOA, NC_2_Pin|NXP_CS_Pin|FPGA_CS_Pin|NXP_RST_Pin
                          |RENESANS_RST_Pin, GPIO_PIN_RESET);

  /*Configure GPIO pin Output Level */
  HAL_GPIO_WritePin(GPIOB, NRF24L01_CS_Pin|FRAM_CS_Pin|INFINEON_RST_Pin|RENESANS_CS_Pin
                          |INFINEON_CS_Pin|WATCHDOG_FEED_Pin|GPS_RST_Pin|NC_1_Pin, GPIO_PIN_RESET);

  /*Configure GPIO pins : FPGA_RST_Pin KILL_SWITCH_Pin NRF24L01_CE_Pin */
  GPIO_InitStruct.Pin = FPGA_RST_Pin|KILL_SWITCH_Pin|NRF24L01_CE_Pin;
  GPIO_InitStruct.Mode = GPIO_MODE_OUTPUT_PP;
  GPIO_InitStruct.Pull = GPIO_NOPULL;
  GPIO_InitStruct.Speed = GPIO_SPEED_FREQ_LOW;
  HAL_GPIO_Init(GPIOC, &GPIO_InitStruct);

  /*Configure GPIO pins : ARM_GUN_Pin FIRE_GUN_Pin */
  GPIO_InitStruct.Pin = ARM_GUN_Pin|FIRE_GUN_Pin;
  GPIO_InitStruct.Mode = GPIO_MODE_OUTPUT_PP;
  GPIO_InitStruct.Pull = GPIO_NOPULL;
  GPIO_InitStruct.Speed = GPIO_SPEED_FREQ_LOW;
  HAL_GPIO_Init(GPIOF, &GPIO_InitStruct);

  /*Configure GPIO pins : NC_2_Pin NXP_CS_Pin FPGA_CS_Pin NXP_RST_Pin
                           RENESANS_RST_Pin */
  GPIO_InitStruct.Pin = NC_2_Pin|NXP_CS_Pin|FPGA_CS_Pin|NXP_RST_Pin
                          |RENESANS_RST_Pin;
  GPIO_InitStruct.Mode = GPIO_MODE_OUTPUT_PP;
  GPIO_InitStruct.Pull = GPIO_NOPULL;
  GPIO_InitStruct.Speed = GPIO_SPEED_FREQ_LOW;
  HAL_GPIO_Init(GPIOA, &GPIO_InitStruct);

  /*Configure GPIO pins : NRF24L01_CS_Pin FRAM_CS_Pin INFINEON_RST_Pin RENESANS_CS_Pin
                           INFINEON_CS_Pin WATCHDOG_FEED_Pin GPS_RST_Pin NC_1_Pin */
  GPIO_InitStruct.Pin = NRF24L01_CS_Pin|FRAM_CS_Pin|INFINEON_RST_Pin|RENESANS_CS_Pin
                          |INFINEON_CS_Pin|WATCHDOG_FEED_Pin|GPS_RST_Pin|NC_1_Pin;
  GPIO_InitStruct.Mode = GPIO_MODE_OUTPUT_PP;
  GPIO_InitStruct.Pull = GPIO_NOPULL;
  GPIO_InitStruct.Speed = GPIO_SPEED_FREQ_LOW;
  HAL_GPIO_Init(GPIOB, &GPIO_InitStruct);

  /*Configure GPIO pin : NRF24L01_IRQ_Pin */
  GPIO_InitStruct.Pin = NRF24L01_IRQ_Pin;
  GPIO_InitStruct.Mode = GPIO_MODE_IT_FALLING;
  GPIO_InitStruct.Pull = GPIO_NOPULL;
  HAL_GPIO_Init(NRF24L01_IRQ_GPIO_Port, &GPIO_InitStruct);

  /* EXTI interrupt init*/
  HAL_NVIC_SetPriority(EXTI2_IRQn, 5, 0);
  HAL_NVIC_EnableIRQ(EXTI2_IRQn);

}

void HAL_TIM_PeriodElapsedCallback(TIM_HandleTypeDef *htim)
{
  if (htim->Instance == TIM6)
  {
    HAL_IncTick();
  }
}

void Error_Handler(void)
{
  __disable_irq();
  while (1)
  {
  }
}
